# IWRL6432 register map
File version: 1.0
CPU: CM4 1.0, other endian, MPU, FPU, 3 interrupt priority bits
Registers are 32-bit, read-write, reset 0x0 unless marked. A register's access mark holds for its fields unless they carry their own. Offsets are from the block's base; [hi:lo] are bit positions; 'fields as' and 'values as' point back to an identical list.

## APP_ECC_AGG
Base 0x56F7EC00
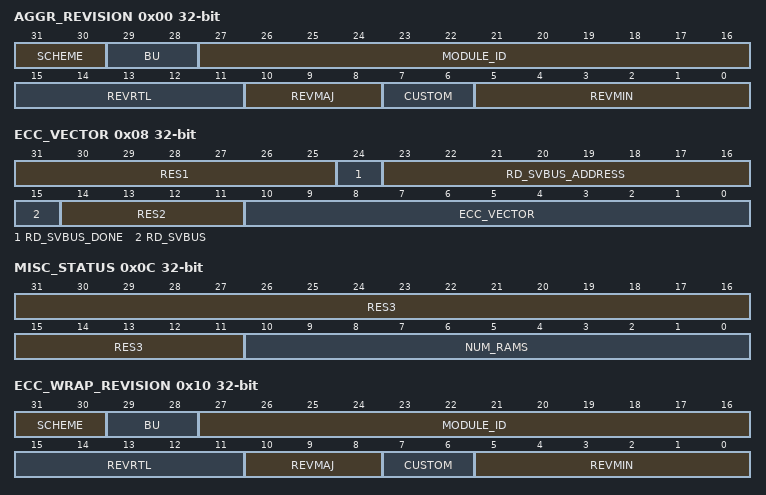
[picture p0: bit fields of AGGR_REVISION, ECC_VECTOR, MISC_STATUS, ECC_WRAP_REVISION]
0x00 AGGR_REVISION — Revision parameters
  [31:30] SCHEME — [31:30] Scheme - (RO )
  [29:28] BU — [29:28] bu - (RO )
  [27:16] MODULE_ID — [27:16] Module ID - (RO )
  [15:11] REVRTL — [15:11] RTL version - (RO )
  [10:8] REVMAJ — [10:8] Major version - (RO )
  [7:6] CUSTOM — [7:6] Custom version - (RO )
  [5:0] REVMIN — [5:0] Minor version - (RO )
0x08 ECC_VECTOR
  [31:25] RES1 — [31:25] RESERVE FIELD
  [24] RD_SVBUS_DONE — [24:24] Status to indicate if read on serial VBUS is complete - (RO )
  [23:16] RD_SVBUS_ADDRESS — [23:16] Read address - (RW )
  [15] RD_SVBUS — [15:15] Write 1 to trigger a read on the serial VBUS - (RW )
  [14:11] RES2 — [14:11] RESERVE FIELD
  [10:0] ECC_VECTOR — [10:0] Value written to select the corresponding ECC RAM for control or status - (RW )
0x0C MISC_STATUS
  [31:11] RES3 — [31:11] RESERVE FIELD
  [10:0] NUM_RAMS — [10:0] Indicates the number of RAMS serviced by the ECC aggregator - (RO )
0x10 ECC_WRAP_REVISION — Revision parameters
  fields as AGGR_REVISION
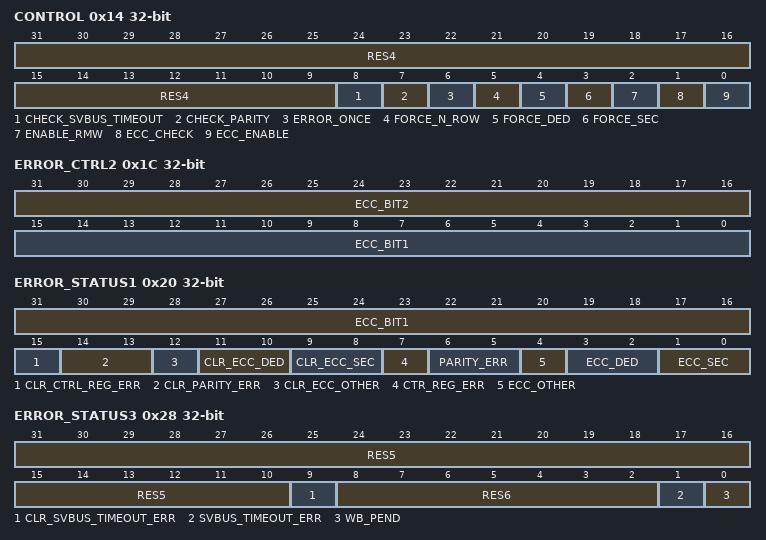
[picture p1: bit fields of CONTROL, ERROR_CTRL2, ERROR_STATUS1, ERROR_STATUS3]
0x14 CONTROL — ECC Control Register
  [31:9] RES4 — [31:9] RESERVE FIELD
  [8] CHECK_SVBUS_TIMEOUT — [8:8] check for svbus timeout errors - (RW )
  [7] CHECK_PARITY — [7:7] check for parity errors - (RW )
  [6] ERROR_ONCE — [6:6] Force Error only once - (RW )
  [5] FORCE_N_ROW — [5:5] Force Error on any RAM read - (RW )
  [4] FORCE_DED — [4:4] Force Double Bit Error - (RW )
  [3] FORCE_SEC — [3:3] Force Single Bit Error - (RW )
  [2] ENABLE_RMW — [2:2] Enable rmw - (RW )
  [1] ECC_CHECK — [1:1] Enable ECC check - (RW )
  [0] ECC_ENABLE — [0:0] Enable ECC - (RW )
0x18 ERROR_CTRL1 — ECC Error Control1 Register
  [31:0] ECC_ROW — [31:0] Row address where single or double-bit error needs to be applied. This is ignored if force_n_row is set - (RW )
0x1C ERROR_CTRL2 — ECC Error Control2 Register
  [31:16] ECC_BIT2 — [31:16] Data bit that needs to be flipped if double bit error needs to be forced - (RW )
  [15:0] ECC_BIT1 — [15:0] Data bit that needs to be flipped when force_sec is set - (RW )
0x20 ERROR_STATUS1 — ECC Error Status1 Register
  [31:16] ECC_BIT1 — [31:16] Data bit that corresponds to the single-bit error - (RO )
  [15] CLR_CTRL_REG_ERR — [15:15] Clear control reg error Error Status you must also re write the contorl ergister itself to clear this - (RW )
  [14:13] CLR_PARITY_ERR — [14:13] Clear parity Error Status - (RW decr)
  [12] CLR_ECC_OTHER — [12:12] Clear other Error Status - (RW )
  [11:10] CLR_ECC_DED — [11:10] Clear Double Bit Error Status - (RW decr)
  [9:8] CLR_ECC_SEC — [9:8] Clear Single Bit Error Status - (RW decr)
  [7] CTR_REG_ERR — [7:7] control register error pending Level interrupt - (RW
  [6:5] PARITY_ERR — [6:5] Level parity error Error Status - (RW )
  [4] ECC_OTHER — [4:4] successive single-bit errors have occurred while a writeback is still pending Level interrupt - (RW
  [3:2] ECC_DED — [3:2] Level Double Bit Error Status - (RW incr)
  [1:0] ECC_SEC — [1:0] Level Single Bit Error Status - (RW incr)
0x24 ERROR_STATUS2 — ECC Error Status2 Register
  [31:0] ECC_ROW — [31:0] Row address where the single or double-bit error has occurred - (RO )
0x28 ERROR_STATUS3 — ECC Error Status3 Register
  [31:10] RES5 — [31:10] RESERVE FIELD
  [9] CLR_SVBUS_TIMEOUT_ERR — [9:9] Clear svbus timeout Error Status - (RW )
  [8:2] RES6 — [8:2] RESERVE FIELD
  [1] SVBUS_TIMEOUT_ERR — [1:1] Level svbus timeout error Error Status - (RW )
  [0] WB_PEND — [0:0] delayed write back pending Status - (RO )
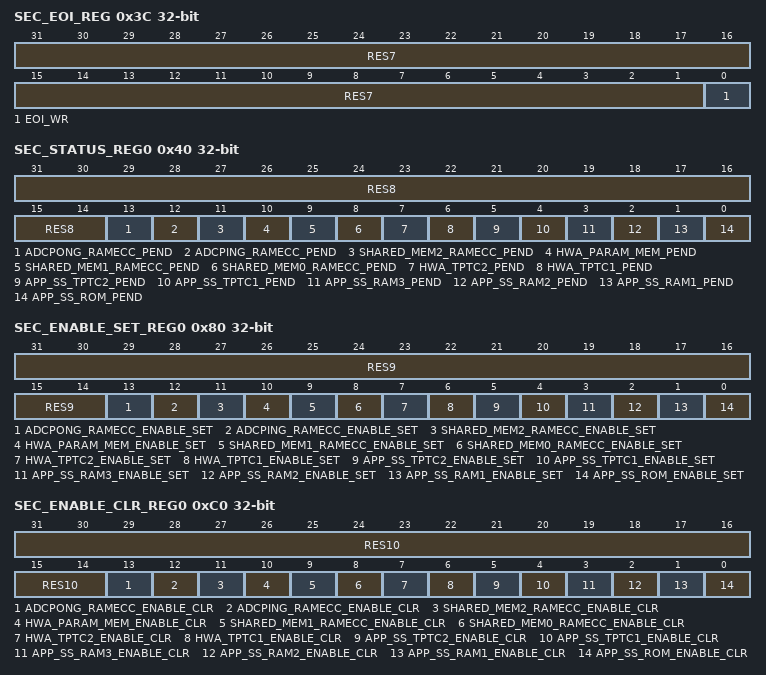
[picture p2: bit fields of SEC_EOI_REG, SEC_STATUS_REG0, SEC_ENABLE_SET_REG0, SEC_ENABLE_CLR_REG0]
0x3C SEC_EOI_REG — EOI Register
  [31:1] RES7 — [31:1] RESERVE FIELD
  [0] EOI_WR — [0:0] EOI Register - (RW )
0x40 SEC_STATUS_REG0 — Interrupt Status Register 0
  [31:14] RES8 — [31:14] RESERVE FIELD
  [13] ADCPONG_RAMECC_PEND — [13:13] Interrupt Pending Status for adcpong_ramecc_pend - (RW )
  [12] ADCPING_RAMECC_PEND — [12:12] Interrupt Pending Status for adcping_ramecc_pend - (RW )
  [11] SHARED_MEM2_RAMECC_PEND — [11:11] Interrupt Pending Status for shared_mem2_ramecc_pend - (RW )
  [10] HWA_PARAM_MEM_PEND — [10:10] Interrupt Pending Status for hwa_param_mem_pend - (RW )
  [9] SHARED_MEM1_RAMECC_PEND — [9:9] Interrupt Pending Status for shared_mem1_ramecc_pend - (RW )
  [8] SHARED_MEM0_RAMECC_PEND — [8:8] Interrupt Pending Status for shared_mem0_ramecc_pend - (RW )
  [7] HWA_TPTC2_PEND — [7:7] Interrupt Pending Status for hwa_tptc2_pend - (RW )
  [6] HWA_TPTC1_PEND — [6:6] Interrupt Pending Status for hwa_tptc1_pend - (RW )
  [5] APP_SS_TPTC2_PEND — [5:5] Interrupt Pending Status for app_ss_tptc2_pend - (RW )
  [4] APP_SS_TPTC1_PEND — [4:4] Interrupt Pending Status for app_ss_tptc1_pend - (RW )
  [3] APP_SS_RAM3_PEND — [3:3] Interrupt Pending Status for app_ss_ram3_pend - (RW )
  [2] APP_SS_RAM2_PEND — [2:2] Interrupt Pending Status for app_ss_ram2_pend - (RW )
  [1] APP_SS_RAM1_PEND — [1:1] Interrupt Pending Status for app_ss_ram1_pend - (RW )
  [0] APP_SS_ROM_PEND — [0:0] Interrupt Pending Status for app_ss_rom_pend - (RW )
0x80 SEC_ENABLE_SET_REG0 — Interrupt Enable Set Register 0
  [31:14] RES9 — [31:14] RESERVE FIELD
  [13] ADCPONG_RAMECC_ENABLE_SET — [13:13] Interrupt Enable Set Register for adcpong_ramecc_pend - (RW )
  [12] ADCPING_RAMECC_ENABLE_SET — [12:12] Interrupt Enable Set Register for adcping_ramecc_pend - (RW )
  [11] SHARED_MEM2_RAMECC_ENABLE_SET — [11:11] Interrupt Enable Set Register for shared_mem2_ramecc_pend - (RW )
  [10] HWA_PARAM_MEM_ENABLE_SET — [10:10] Interrupt Enable Set Register for hwa_param_mem_pend - (RW )
  [9] SHARED_MEM1_RAMECC_ENABLE_SET — [9:9] Interrupt Enable Set Register for shared_mem1_ramecc_pend - (RW )
  [8] SHARED_MEM0_RAMECC_ENABLE_SET — [8:8] Interrupt Enable Set Register for shared_mem0_ramecc_pend - (RW )
  [7] HWA_TPTC2_ENABLE_SET — [7:7] Interrupt Enable Set Register for hwa_tptc2_pend - (RW )
  [6] HWA_TPTC1_ENABLE_SET — [6:6] Interrupt Enable Set Register for hwa_tptc1_pend - (RW )
  [5] APP_SS_TPTC2_ENABLE_SET — [5:5] Interrupt Enable Set Register for app_ss_tptc2_pend - (RW )
  [4] APP_SS_TPTC1_ENABLE_SET — [4:4] Interrupt Enable Set Register for app_ss_tptc1_pend - (RW )
  [3] APP_SS_RAM3_ENABLE_SET — [3:3] Interrupt Enable Set Register for app_ss_ram3_pend - (RW )
  [2] APP_SS_RAM2_ENABLE_SET — [2:2] Interrupt Enable Set Register for app_ss_ram2_pend - (RW )
  [1] APP_SS_RAM1_ENABLE_SET — [1:1] Interrupt Enable Set Register for app_ss_ram1_pend - (RW )
  [0] APP_SS_ROM_ENABLE_SET — [0:0] Interrupt Enable Set Register for app_ss_rom_pend - (RW )
0xC0 SEC_ENABLE_CLR_REG0 — Interrupt Enable Clear Register 0
  [31:14] RES10 — [31:14] RESERVE FIELD
  [13] ADCPONG_RAMECC_ENABLE_CLR — [13:13] Interrupt Enable Clear Register for adcpong_ramecc_pend - (RW )
  [12] ADCPING_RAMECC_ENABLE_CLR — [12:12] Interrupt Enable Clear Register for adcping_ramecc_pend - (RW )
  [11] SHARED_MEM2_RAMECC_ENABLE_CLR — [11:11] Interrupt Enable Clear Register for shared_mem2_ramecc_pend - (RW )
  [10] HWA_PARAM_MEM_ENABLE_CLR — [10:10] Interrupt Enable Clear Register for hwa_param_mem_pend - (RW )
  [9] SHARED_MEM1_RAMECC_ENABLE_CLR — [9:9] Interrupt Enable Clear Register for shared_mem1_ramecc_pend - (RW )
  [8] SHARED_MEM0_RAMECC_ENABLE_CLR — [8:8] Interrupt Enable Clear Register for shared_mem0_ramecc_pend - (RW )
  [7] HWA_TPTC2_ENABLE_CLR — [7:7] Interrupt Enable Clear Register for hwa_tptc2_pend - (RW )
  [6] HWA_TPTC1_ENABLE_CLR — [6:6] Interrupt Enable Clear Register for hwa_tptc1_pend - (RW )
  [5] APP_SS_TPTC2_ENABLE_CLR — [5:5] Interrupt Enable Clear Register for app_ss_tptc2_pend - (RW )
  [4] APP_SS_TPTC1_ENABLE_CLR — [4:4] Interrupt Enable Clear Register for app_ss_tptc1_pend - (RW )
  [3] APP_SS_RAM3_ENABLE_CLR — [3:3] Interrupt Enable Clear Register for app_ss_ram3_pend - (RW )
  [2] APP_SS_RAM2_ENABLE_CLR — [2:2] Interrupt Enable Clear Register for app_ss_ram2_pend - (RW )
  [1] APP_SS_RAM1_ENABLE_CLR — [1:1] Interrupt Enable Clear Register for app_ss_ram1_pend - (RW )
  [0] APP_SS_ROM_ENABLE_CLR — [0:0] Interrupt Enable Clear Register for app_ss_rom_pend - (RW )
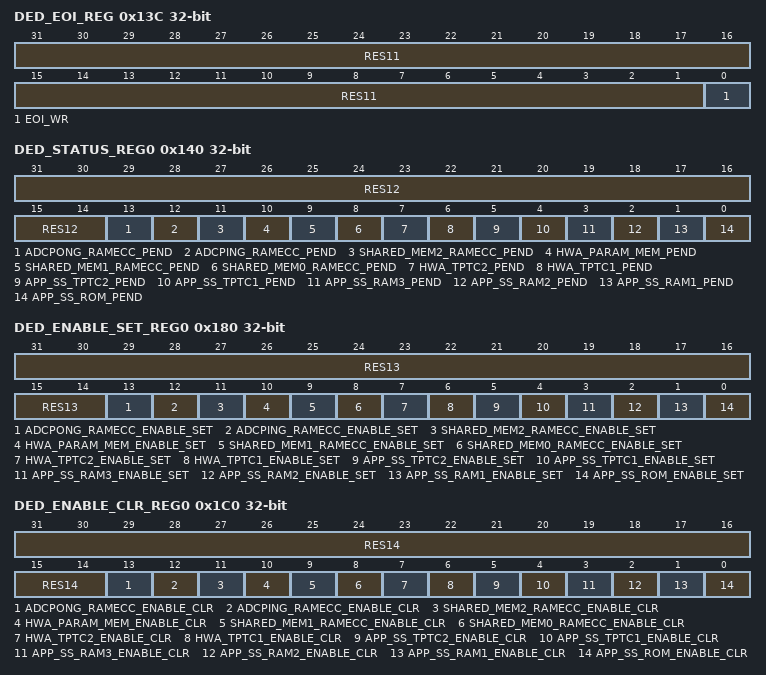
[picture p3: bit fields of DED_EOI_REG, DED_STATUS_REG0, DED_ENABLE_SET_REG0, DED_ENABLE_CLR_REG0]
0x13C DED_EOI_REG — EOI Register
  [31:1] RES11 — [31:1] RESERVE FIELD
  [0] EOI_WR — [0:0] EOI Register - (RW )
0x140 DED_STATUS_REG0 — Interrupt Status Register 0
  [31:14] RES12 — [31:14] RESERVE FIELD
  [13] ADCPONG_RAMECC_PEND — [13:13] Interrupt Pending Status for adcpong_ramecc_pend - (RW )
  [12] ADCPING_RAMECC_PEND — [12:12] Interrupt Pending Status for adcping_ramecc_pend - (RW )
  [11] SHARED_MEM2_RAMECC_PEND — [11:11] Interrupt Pending Status for shared_mem2_ramecc_pend - (RW )
  [10] HWA_PARAM_MEM_PEND — [10:10] Interrupt Pending Status for hwa_param_mem_pend - (RW )
  [9] SHARED_MEM1_RAMECC_PEND — [9:9] Interrupt Pending Status for shared_mem1_ramecc_pend - (RW )
  [8] SHARED_MEM0_RAMECC_PEND — [8:8] Interrupt Pending Status for shared_mem0_ramecc_pend - (RW )
  [7] HWA_TPTC2_PEND — [7:7] Interrupt Pending Status for hwa_tptc2_pend - (RW )
  [6] HWA_TPTC1_PEND — [6:6] Interrupt Pending Status for hwa_tptc1_pend - (RW )
  [5] APP_SS_TPTC2_PEND — [5:5] Interrupt Pending Status for app_ss_tptc2_pend - (RW )
  [4] APP_SS_TPTC1_PEND — [4:4] Interrupt Pending Status for app_ss_tptc1_pend - (RW )
  [3] APP_SS_RAM3_PEND — [3:3] Interrupt Pending Status for app_ss_ram3_pend - (RW )
  [2] APP_SS_RAM2_PEND — [2:2] Interrupt Pending Status for app_ss_ram2_pend - (RW )
  [1] APP_SS_RAM1_PEND — [1:1] Interrupt Pending Status for app_ss_ram1_pend - (RW )
  [0] APP_SS_ROM_PEND — [0:0] Interrupt Pending Status for app_ss_rom_pend - (RW )
0x180 DED_ENABLE_SET_REG0 — Interrupt Enable Set Register 0
  [31:14] RES13 — [31:14] RESERVE FIELD
  [13] ADCPONG_RAMECC_ENABLE_SET — [13:13] Interrupt Enable Set Register for adcpong_ramecc_pend - (RW )
  [12] ADCPING_RAMECC_ENABLE_SET — [12:12] Interrupt Enable Set Register for adcping_ramecc_pend - (RW )
  [11] SHARED_MEM2_RAMECC_ENABLE_SET — [11:11] Interrupt Enable Set Register for shared_mem2_ramecc_pend - (RW )
  [10] HWA_PARAM_MEM_ENABLE_SET — [10:10] Interrupt Enable Set Register for hwa_param_mem_pend - (RW )
  [9] SHARED_MEM1_RAMECC_ENABLE_SET — [9:9] Interrupt Enable Set Register for shared_mem1_ramecc_pend - (RW )
  [8] SHARED_MEM0_RAMECC_ENABLE_SET — [8:8] Interrupt Enable Set Register for shared_mem0_ramecc_pend - (RW )
  [7] HWA_TPTC2_ENABLE_SET — [7:7] Interrupt Enable Set Register for hwa_tptc2_pend - (RW )
  [6] HWA_TPTC1_ENABLE_SET — [6:6] Interrupt Enable Set Register for hwa_tptc1_pend - (RW )
  [5] APP_SS_TPTC2_ENABLE_SET — [5:5] Interrupt Enable Set Register for app_ss_tptc2_pend - (RW )
  [4] APP_SS_TPTC1_ENABLE_SET — [4:4] Interrupt Enable Set Register for app_ss_tptc1_pend - (RW )
  [3] APP_SS_RAM3_ENABLE_SET — [3:3] Interrupt Enable Set Register for app_ss_ram3_pend - (RW )
  [2] APP_SS_RAM2_ENABLE_SET — [2:2] Interrupt Enable Set Register for app_ss_ram2_pend - (RW )
  [1] APP_SS_RAM1_ENABLE_SET — [1:1] Interrupt Enable Set Register for app_ss_ram1_pend - (RW )
  [0] APP_SS_ROM_ENABLE_SET — [0:0] Interrupt Enable Set Register for app_ss_rom_pend - (RW )
0x1C0 DED_ENABLE_CLR_REG0 — Interrupt Enable Clear Register 0
  [31:14] RES14 — [31:14] RESERVE FIELD
  [13] ADCPONG_RAMECC_ENABLE_CLR — [13:13] Interrupt Enable Clear Register for adcpong_ramecc_pend - (RW )
  [12] ADCPING_RAMECC_ENABLE_CLR — [12:12] Interrupt Enable Clear Register for adcping_ramecc_pend - (RW )
  [11] SHARED_MEM2_RAMECC_ENABLE_CLR — [11:11] Interrupt Enable Clear Register for shared_mem2_ramecc_pend - (RW )
  [10] HWA_PARAM_MEM_ENABLE_CLR — [10:10] Interrupt Enable Clear Register for hwa_param_mem_pend - (RW )
  [9] SHARED_MEM1_RAMECC_ENABLE_CLR — [9:9] Interrupt Enable Clear Register for shared_mem1_ramecc_pend - (RW )
  [8] SHARED_MEM0_RAMECC_ENABLE_CLR — [8:8] Interrupt Enable Clear Register for shared_mem0_ramecc_pend - (RW )
  [7] HWA_TPTC2_ENABLE_CLR — [7:7] Interrupt Enable Clear Register for hwa_tptc2_pend - (RW )
  [6] HWA_TPTC1_ENABLE_CLR — [6:6] Interrupt Enable Clear Register for hwa_tptc1_pend - (RW )
  [5] APP_SS_TPTC2_ENABLE_CLR — [5:5] Interrupt Enable Clear Register for app_ss_tptc2_pend - (RW )
  [4] APP_SS_TPTC1_ENABLE_CLR — [4:4] Interrupt Enable Clear Register for app_ss_tptc1_pend - (RW )
  [3] APP_SS_RAM3_ENABLE_CLR — [3:3] Interrupt Enable Clear Register for app_ss_ram3_pend - (RW )
  [2] APP_SS_RAM2_ENABLE_CLR — [2:2] Interrupt Enable Clear Register for app_ss_ram2_pend - (RW )
  [1] APP_SS_RAM1_ENABLE_CLR — [1:1] Interrupt Enable Clear Register for app_ss_ram1_pend - (RW )
  [0] APP_SS_ROM_ENABLE_CLR — [0:0] Interrupt Enable Clear Register for app_ss_rom_pend - (RW )
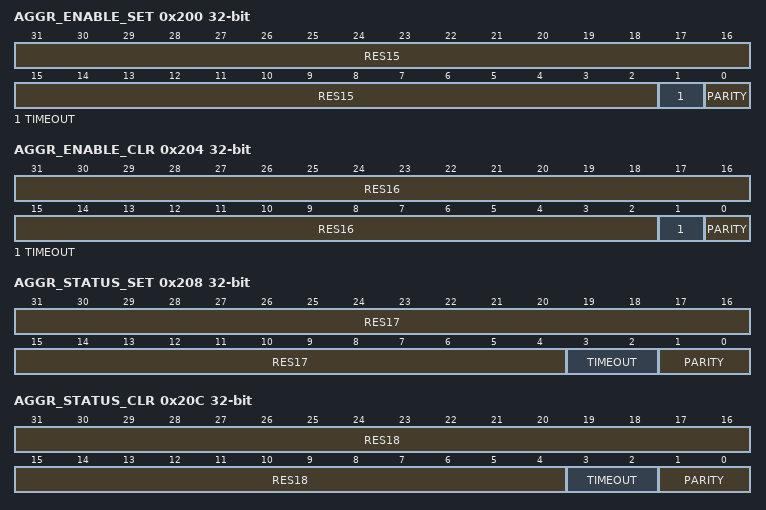
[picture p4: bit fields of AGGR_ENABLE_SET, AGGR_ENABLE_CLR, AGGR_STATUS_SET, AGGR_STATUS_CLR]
0x200 AGGR_ENABLE_SET — AGGR interrupt enable set Register
  [31:2] RES15 — [31:2] RESERVE FIELD
  [1] TIMEOUT — [1:1] interrupt enable set for svbus timeout errors - (RW )
  [0] PARITY — [0:0] interrupt enable set for parity errors - (RW )
0x204 AGGR_ENABLE_CLR — AGGR interrupt enable clear Register
  [31:2] RES16 — [31:2] RESERVE FIELD
  [1] TIMEOUT — [1:1] interrupt enable clear for svbus timeout errors - (RW )
  [0] PARITY — [0:0] interrupt enable clear for parity errors - (RW )
0x208 AGGR_STATUS_SET — AGGR interrupt status set Register
  [31:4] RES17 — [31:4] RESERVE FIELD
  [3:2] TIMEOUT — [3:2] interrupt status set for svbus timeout errors - (RW incr)
  [1:0] PARITY — [1:0] interrupt status set for parity errors - (RW incr)
0x20C AGGR_STATUS_CLR — AGGR interrupt status clear Register
  [31:4] RES18 — [31:4] RESERVE FIELD
  [3:2] TIMEOUT — [3:2] interrupt status clear for svbus timeout errors - (RW decr)
  [1:0] PARITY — [1:0] interrupt status clear for parity errors - (RW decr)
